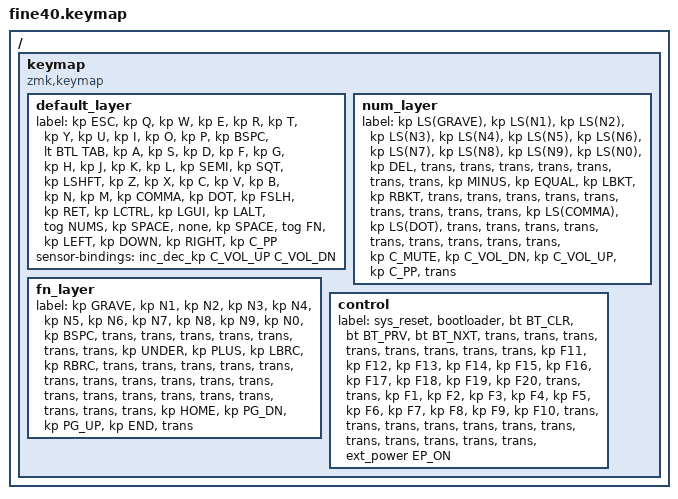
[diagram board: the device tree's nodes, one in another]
/*
 * Aidan Smith (2021)
 * hope this works
 * SPDX-License-Identifier: MIT
 */

#include <behaviors.dtsi>
#include <dt-bindings/zmk/keys.h>
#include <dt-bindings/zmk/bt.h>
#include <dt-bindings/zmk/ext_power.h>

#define DEFAULT 0
#define NUMS 1
#define FN 2
#define BTL 3

/ {
	keymap {
		compatible = "zmk,keymap";

		default_layer {
      label = "base"
      // -------------------------------------------------------------------------------------
      // |  ESC  |  Q   |  W   |  E   |  R   |  T   |  Y   |  U   |  I   |  O   |  P   | BSPC |
      // |  TAB  |  A   |  S   |  D   |  F   |  G   |  H   |  J   |  K   |  L   |  ;   |  '   |
      // | SHIFT |  Z   |  X   |  C   |  V   |  B   |  N   |  M   |  ,   |  .   |  /   | RET  |
      // | LCTRL | LGUI | LALT | LOWR |   SPC   |   SPC    | RAIS | LEFT | DOWN |RIGHT | P/P  |
			bindings = <
				&kp ESC   &kp Q    &kp W    &kp E    &kp R &kp T     &kp Y       &kp U     &kp I     &kp O     &kp P     &kp BSPC
				&lt BTL TAB &kp A  &kp S    &kp D    &kp F &kp G     &kp H       &kp J     &kp K     &kp L     &kp SEMI  &kp SQT
				&kp LSHFT &kp Z    &kp X    &kp C    &kp V &kp B     &kp N       &kp M     &kp COMMA &kp DOT   &kp FSLH  &kp RET
				&kp LCTRL &kp LGUI &kp LALT &tog NUMS &kp SPACE &none &kp SPACE  &tog FN   &kp LEFT  &kp DOWN  &kp RIGHT &kp C_PP
			>;

			sensor-bindings = <&inc_dec_kp C_VOL_UP C_VOL_DN>;
		};

		num_layer {
      label = "num"
			bindings = <
				&kp LS(GRAVE) &kp LS(N1) &kp LS(N2) &kp LS(N3) &kp LS(N4) &kp LS(N5) &kp LS(N6) &kp LS(N7) &kp LS(N8)    &kp LS(N9)   &kp LS(N0) &kp DEL
				&trans        &trans 	 &trans     &trans     &trans     &trans     &trans     &kp MINUS  &kp EQUAL     &kp LBKT     &kp RBKT   &trans
				&trans        &trans     &trans     &trans     &trans     &trans     &trans     &trans     &kp LS(COMMA) &kp LS(DOT)  &trans     &trans
				&trans        &trans     &trans     &trans     &trans     &trans     &trans     &kp C_MUTE &kp C_VOL_DN  &kp C_VOL_UP &kp C_PP   &trans
			>;
		};

		fn_layer {
      label = "fn"
			bindings = <
				&kp GRAVE &kp N1 &kp N2 &kp N3 &kp N4 &kp N5 &kp N6 &kp N7    &kp N8    &kp N9    &kp N0   &kp BSPC
				&trans    &trans &trans &trans &trans &trans &trans &kp UNDER &kp PLUS  &kp LBRC  &kp RBRC &trans
				&trans    &trans &trans &trans &trans &trans &trans &trans    &trans    &trans    &trans   &trans
				&trans    &trans &trans &trans &trans &trans &trans &kp HOME  &kp PG_DN &kp PG_UP &kp END  &trans
			>;
		};

		control {
      label = "ctrl"
			bindings = <
				&sys_reset &bootloader &bt BT_CLR &bt BT_PRV &bt BT_NXT &trans  &trans  &trans  &trans  &trans  &trans  &trans
				&trans     &kp F11     &kp F12    &kp F13    &kp F14    &kp F15 &kp F16 &kp F17 &kp F18 &kp F19 &kp F20 &trans
				&trans     &kp F1      &kp F2     &kp F3     &kp F4     &kp F5  &kp F6  &kp F7  &kp F8  &kp F9  &kp F10 &trans
				&trans     &trans      &trans     &trans     &trans     &trans  &trans  &trans  &trans  &trans  &trans  &ext_power EP_ON
			>;
		};
	};
};
